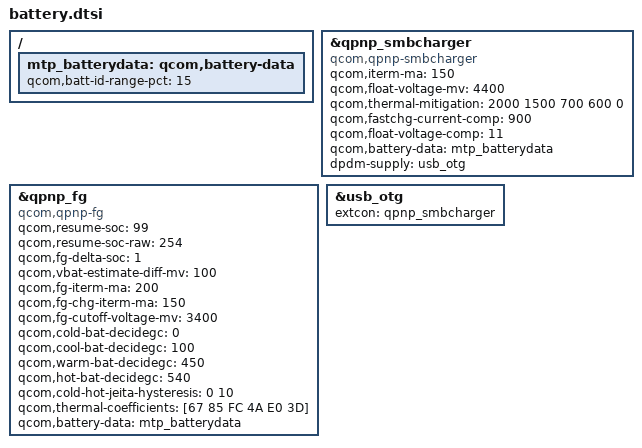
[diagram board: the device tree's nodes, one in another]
/{
	mtp_batterydata: qcom,battery-data {
		qcom,batt-id-range-pct = <15>;
		#include "../common/batterydata/batterydata-coslight-4000mah-4400mv.dtsi"
		#include "../common/batterydata/batterydata-coslight-4000mah-4400mv-10k.dtsi"
		#include "../common/batterydata/batterydata-sunwoda-4000mah-4400mv.dtsi"
		#include "../common/batterydata/batterydata-scud-4000mah-4400mv.dtsi"
	};
};

&qpnp_smbcharger {
	compatible = "qcom,qpnp-smbcharger";
    qcom,iterm-ma = <150>;
	qcom,float-voltage-mv = <4400>;
    /delete-property/ qcom,parallel-usb-min-current-ma;
	/delete-property/ qcom,parallel-usb-9v-min-current-ma;
	/delete-property/ qcom,parallel-allowed-lowering-ma;
    qcom,thermal-mitigation = <2000 1500 700 600 0>;
	qcom,fastchg-current-comp = <900>;
	qcom,float-voltage-comp = <11>;
    /delete-property/ qcom,external-typec;
	/delete-property/ qcom,typec-psy-name;
    qcom,battery-data = <&mtp_batterydata>;
	dpdm-supply = <&usb_otg>;
	status = "okay";
};

&qpnp_fg {
	compatible = "qcom,qpnp-fg";
    qcom,resume-soc = <99>;
	qcom,resume-soc-raw = <254>;
	qcom,fg-delta-soc = <1>;
	qcom,vbat-estimate-diff-mv = <100>;
    qcom,fg-iterm-ma = <200>;
	qcom,fg-chg-iterm-ma = <150>;
    qcom,fg-cutoff-voltage-mv = <3400>;
	qcom,cold-bat-decidegc = <0>;
	qcom,cool-bat-decidegc = <100>;
	qcom,warm-bat-decidegc = <450>;
	qcom,hot-bat-decidegc = <540>;
	qcom,cold-hot-jeita-hysteresis = <0 10>;/*60->58 recharge*/
	qcom,thermal-coefficients = [67 85 FC 4A E0 3D];
    qcom,battery-data = <&mtp_batterydata>;
	status = "okay";
};

&usb_otg {
	extcon = <&qpnp_smbcharger>;
};

